# F28x7x_cla_regs register map
Vendor: Texas Instruments
Peripheral module from a debugger description file (folder C2000).
Address unit: 16 bits
Registers are 16-bit, read-write, no defined reset value unless marked. A register's access mark holds for its fields unless they carry their own. Offsets are as the file gives them; lines under a group give offsets from that group; [hi:lo] are bit positions; {n}, {i} and the like mark numbered series; 'fields as' and 'values as' point back to an identical list; <NAME> marks a mode.

## CLA_REGS — CLA Registers
0x00 MVECT1 — Task Interrupt Vector
  [15:0] MVECT — Offset of the first instruction
0x01 MVECT2 — Task Interrupt Vector
  [15:0] MVECT — Offset of the first instruction
0x02 MVECT3 — Task Interrupt Vector
  [15:0] MVECT — Offset of the first instruction
0x03 MVECT4 — Task Interrupt Vector
  [15:0] MVECT — Offset of the first instruction
0x04 MVECT5 — Task Interrupt Vector
  [15:0] MVECT — Offset of the first instruction
0x05 MVECT6 — Task Interrupt Vector
  [15:0] MVECT — Offset of the first instruction
0x06 MVECT7 — Task Interrupt Vector
  [15:0] MVECT — Offset of the first instruction
0x07 MVECT8 — Task Interrupt Vector
  [15:0] MVECT — Offset of the first instruction
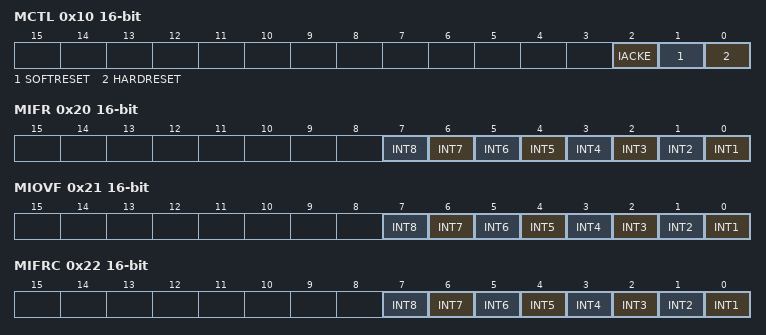
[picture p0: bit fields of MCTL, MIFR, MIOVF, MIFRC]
0x10 MCTL — Control Register
  [2] IACKE — IACK enable
  [1] SOFTRESET
  [0] HARDRESET
0x20 MIFR ro — Interrupt Flag Register
  [n-1] INT{n} (n=1..8) — Task {n} Interrupt Flag
0x21 MIOVF ro — Interrupt Overflow Flag Register
  [n-1] INT{n} (n=1..8) — Task {n} Interrupt Overflow Flag
0x22 MIFRC — Interrupt Force Register
  [n-1] INT{n} (n=1..8) — Task {n} Interrupt Force
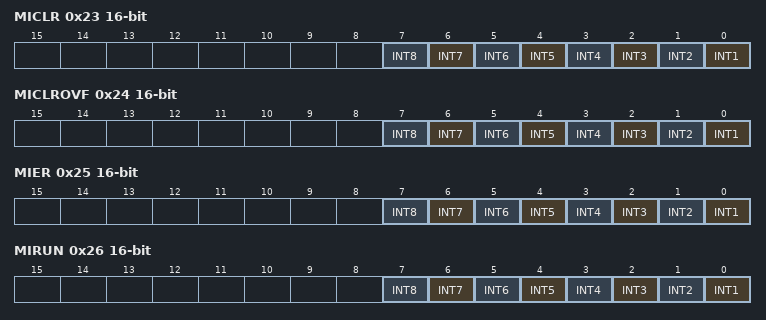
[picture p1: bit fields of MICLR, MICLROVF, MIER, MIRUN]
0x23 MICLR — Interrupt Flag Clear Register
  [n-1] INT{n} (n=1..8) — Task {n} Interrupt Flag Clear
0x24 MICLROVF — Interrupt Overflow Flag Clear Register
  [n-1] INT{n} (n=1..8) — Task {n} Interrupt Overflow Flag Clear
0x25 MIER ro — Interrupt Enable Register
  [n-1] INT{n} (n=1..8) — Task {n} Interrupt Enable
0x26 MIRUN ro — Interrupt Run Status Register
  [n-1] INT{n} (n=1..8) — Task {n} Run Status
0x28 _MPC — CLA Program Counter
  [15:0] _MPC — Points to the instruction
0x2A _MAR0 — CLA Auxiliary Register 0
  [15:0] _MAR0 — CLA Auxillary Register 0
0x2B _MAR1 — CLA Auxiliary Register 1
  [15:0] _MAR1 — CLA Auxillary Register 1
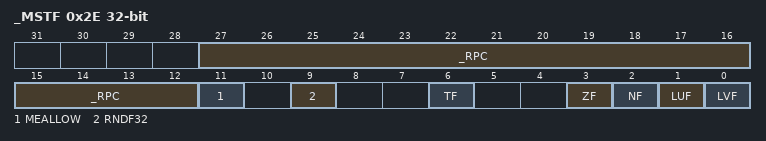
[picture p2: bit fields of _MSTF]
0x2E _MSTF 32-bit — CLA Floating-Point Status Register
  [27:12] _RPC — Return PC
  [11] MEALLOW — MEALLOW Status
  [9] RNDF32 — Round 32-bit Floating-Point Mode
  [6] TF — Test Flag
  [3] ZF — Zero Float Flag
  [2] NF — Negative Float Flag
  [1] LUF — Latched Underflow Flag
  [0] LVF — Latched Overflow Flag
{0x30+4i} _MR{i} 32-bit (i=0..3) — CLA Floating-Point Result Register {i}
  [31:0] i32 — CLA Result Register {i}
